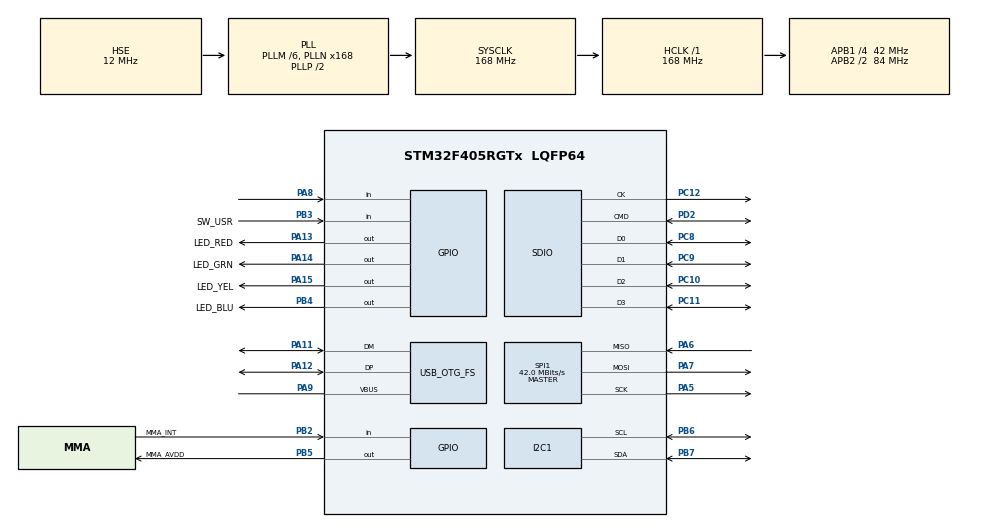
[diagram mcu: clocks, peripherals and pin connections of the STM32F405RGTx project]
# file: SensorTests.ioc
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Dma.Request0=SDIO_RX
Dma.Request1=SDIO_TX
Dma.SDIO_RX.0.Direction=DMA_PERIPH_TO_MEMORY
Dma.SDIO_RX.0.FIFOMode=DMA_FIFOMODE_ENABLE
Dma.SDIO_RX.0.FIFOThreshold=DMA_FIFO_THRESHOLD_FULL
Dma.SDIO_RX.0.Instance=DMA2_Stream3
Dma.SDIO_RX.0.MemBurst=DMA_MBURST_INC4
Dma.SDIO_RX.0.MemDataAlignment=DMA_MDATAALIGN_WORD
Dma.SDIO_RX.0.MemInc=DMA_MINC_ENABLE
Dma.SDIO_RX.0.Mode=DMA_PFCTRL
Dma.SDIO_RX.0.PeriphBurst=DMA_PBURST_INC4
Dma.SDIO_RX.0.PeriphDataAlignment=DMA_PDATAALIGN_WORD
Dma.SDIO_RX.0.PeriphInc=DMA_PINC_DISABLE
Dma.SDIO_RX.0.Priority=DMA_PRIORITY_LOW
Dma.SDIO_TX.1.Direction=DMA_MEMORY_TO_PERIPH
Dma.SDIO_TX.1.FIFOMode=DMA_FIFOMODE_ENABLE
Dma.SDIO_TX.1.FIFOThreshold=DMA_FIFO_THRESHOLD_FULL
Dma.SDIO_TX.1.Instance=DMA2_Stream6
Dma.SDIO_TX.1.MemBurst=DMA_MBURST_INC4
Dma.SDIO_TX.1.MemDataAlignment=DMA_MDATAALIGN_WORD
Dma.SDIO_TX.1.MemInc=DMA_MINC_ENABLE
Dma.SDIO_TX.1.Mode=DMA_PFCTRL
Dma.SDIO_TX.1.PeriphBurst=DMA_PBURST_INC4
Dma.SDIO_TX.1.PeriphDataAlignment=DMA_PDATAALIGN_WORD
Dma.SDIO_TX.1.PeriphInc=DMA_PINC_DISABLE
Dma.SDIO_TX.1.Priority=DMA_PRIORITY_LOW
FATFS.BSP.number=1
FATFS.USE_DMA_CODE_SD=1
FATFS0.BSP.STBoard=false
FATFS0.BSP.api=Unknown
FATFS0.BSP.i2caddr=0
FATFS0.BSP.instance=PA8
FATFS0.BSP.ip=GPIO
FATFS0.BSP.mode=Input
FATFS0.BSP.name=Detect_SDIO
FATFS0.BSP.solution=PA8
Mcu.Family=STM32F4
Mcu.Name=STM32F405RGTx
Mcu.Package=LQFP64
NVIC.DMA2_Stream3_IRQn=true\:0\:0\:false\:false\:true\:false\:true
NVIC.DMA2_Stream6_IRQn=true\:0\:0\:false\:false\:true\:false\:true
NVIC.OTG_FS_IRQn=true\:0\:0\:false\:false\:true\:false\:true
NVIC.PriorityGroup=NVIC_PRIORITYGROUP_4
NVIC.SDIO_IRQn=true\:0\:0\:false\:false\:true\:true\:true
PA11.Mode=Device_Only
PA11.Signal=USB_OTG_FS_DM
PA12.Mode=Device_Only
PA12.Signal=USB_OTG_FS_DP
PA13.GPIO_Label=LED_RED
PA13.Signal=GPIO_Output
PA14.GPIO_Label=LED_GRN
PA14.Signal=GPIO_Output
PA15.GPIO_Label=LED_YEL
PA15.Signal=GPIO_Output
PA5.Mode=Full_Duplex_Master
PA5.Signal=SPI1_SCK
PA6.Mode=Full_Duplex_Master
PA6.Signal=SPI1_MISO
PA7.Mode=Full_Duplex_Master
PA7.Signal=SPI1_MOSI
PA8.Signal=GPIO_Input
PA9.Mode=Activate_VBUS
PA9.Signal=USB_OTG_FS_VBUS
PB2.GPIO_Label=MMA_INT
PB2.Signal=GPIO_Input
PB3.GPIO_Label=SW_USR
PB3.Signal=GPIO_Input
PB4.GPIO_Label=LED_BLU
PB4.Signal=GPIO_Output
PB5.GPIO_Label=MMA_AVDD
PB5.Signal=GPIO_Output
PB6.GPIO_PuPdOD=GPIO_NOPULL
PB6.Mode=I2C
PB6.Signal=I2C1_SCL
PB7.GPIO_PuPdOD=GPIO_NOPULL
PB7.Mode=I2C
PB7.Signal=I2C1_SDA
PC10.GPIO_PuPd=GPIO_PULLUP
PC10.Mode=SD_4_bits_Wide_bus
PC10.Signal=SDIO_D2
PC11.Mode=SD_4_bits_Wide_bus
PC11.Signal=SDIO_D3
PC12.GPIO_PuPd=GPIO_NOPULL
PC12.Mode=SD_4_bits_Wide_bus
PC12.Signal=SDIO_CK
PC14-OSC32_IN.Mode=LSE-External-Oscillator
PC14-OSC32_IN.Signal=RCC_OSC32_IN
PC15-OSC32_OUT.Mode=LSE-External-Oscillator
PC15-OSC32_OUT.Signal=RCC_OSC32_OUT
PC8.GPIO_PuPd=GPIO_PULLUP
PC8.Mode=SD_4_bits_Wide_bus
PC8.Signal=SDIO_D0
PC9.GPIO_PuPd=GPIO_PULLUP
PC9.Mode=SD_4_bits_Wide_bus
PC9.Signal=SDIO_D1
PD2.GPIO_PuPd=GPIO_PULLUP
PD2.Mode=SD_4_bits_Wide_bus
PD2.Signal=SDIO_CMD
PH0-OSC_IN.Mode=HSE-External-Oscillator
PH0-OSC_IN.Signal=RCC_OSC_IN
PH1-OSC_OUT.Mode=HSE-External-Oscillator
PH1-OSC_OUT.Signal=RCC_OSC_OUT
ProjectManager.HeapSize=0x200
ProjectManager.StackSize=0x400
ProjectManager.TargetToolchain=STM32CubeIDE
RCC.48MHZClocksFreq_Value=48000000
RCC.AHBFreq_Value=168000000
RCC.APB1CLKDivider=RCC_HCLK_DIV4
RCC.APB1Freq_Value=42000000
RCC.APB1TimFreq_Value=84000000
RCC.APB2CLKDivider=RCC_HCLK_DIV2
RCC.APB2Freq_Value=84000000
RCC.APB2TimFreq_Value=168000000
RCC.CortexFreq_Value=168000000
RCC.HCLKFreq_Value=168000000
RCC.HSE_VALUE=12000000
RCC.HSI_VALUE=16000000
RCC.PLLM=6
RCC.PLLN=168
RCC.PLLQ=7
RCC.SYSCLKFreq_VALUE=168000000
RCC.SYSCLKSource=RCC_SYSCLKSOURCE_PLLCLK
RCC.VCOOutputFreq_Value=336000000
SPI1.CalculateBaudRate=42.0 MBits/s
SPI1.Direction=SPI_DIRECTION_2LINES
SPI1.Mode=SPI_MODE_MASTER
SPI1.VirtualType=VM_MASTER
USB_DEVICE.CLASS_NAME_FS=CDC
USB_DEVICE.VirtualMode-CDC_FS=Cdc
USB_DEVICE.VirtualModeFS=Cdc_FS
USB_OTG_FS.VirtualMode=Device_Only
VP_FATFS_VS_SDIO.Mode=SDIO
VP_USB_DEVICE_VS_USB_DEVICE_CDC_FS.Mode=CDC_FS
board=custom

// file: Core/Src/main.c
/* USER CODE BEGIN Header */
/**
  ******************************************************************************
  * @file           : main.c
  * @brief          : Main program body
  ******************************************************************************
  * @attention
  *
  * <h2><center>&copy; Copyright (c) 2020 STMicroelectronics.
  * All rights reserved.</center></h2>
  *
  * This software component is licensed by ST under Ultimate Liberty license
  * SLA0044, the "License"; You may not use this file except in compliance with
  * the License. You may obtain a copy of the License at:
  *                             www.st.com/SLA0044
  *
  ******************************************************************************
  */
/* USER CODE END Header */

#include "main.h"
#include "fatfs.h"
#include "usb_device.h"

/* USER CODE BEGIN Includes */
#include "run.c"
/* USER CODE END Includes */

I2C_HandleTypeDef hi2c1;

SD_HandleTypeDef hsd;
DMA_HandleTypeDef hdma_sdio_rx;
DMA_HandleTypeDef hdma_sdio_tx;

SPI_HandleTypeDef hspi1;

void SystemClock_Config(void);
static void MX_GPIO_Init(void);
static void MX_DMA_Init(void);
static void MX_SDIO_SD_Init(void);
static void MX_I2C1_Init(void);
static void MX_SPI1_Init(void);

int main(void)
{

  /* MCU Configuration--------------------------------------------------------*/

  /* Reset of all peripherals, Initializes the Flash interface and the Systick. */
  HAL_Init();

  /* Configure the system clock */
  SystemClock_Config();

  /* Initialize all configured peripherals */
  MX_GPIO_Init();
  MX_DMA_Init();
  MX_SDIO_SD_Init();
  MX_FATFS_Init();
  MX_I2C1_Init();
  MX_SPI1_Init();
  MX_USB_DEVICE_Init();
  /* USER CODE BEGIN 2 */
  setup();
  /* USER CODE END 2 */

  /* Infinite loop */
  while (1)
  {

    /* USER CODE BEGIN 3 */
	loop();
  }
  /* USER CODE END 3 */
}

void SystemClock_Config(void)
{
  RCC_OscInitTypeDef RCC_OscInitStruct = {0};
  RCC_ClkInitTypeDef RCC_ClkInitStruct = {0};

  /** Configure the main internal regulator output voltage
  */
  __HAL_RCC_PWR_CLK_ENABLE();
  __HAL_PWR_VOLTAGESCALING_CONFIG(PWR_REGULATOR_VOLTAGE_SCALE1);
  /** Initializes the CPU, AHB and APB busses clocks
  */
  RCC_OscInitStruct.OscillatorType = RCC_OSCILLATORTYPE_HSE;
  RCC_OscInitStruct.HSEState = RCC_HSE_ON;
  RCC_OscInitStruct.PLL.PLLState = RCC_PLL_ON;
  RCC_OscInitStruct.PLL.PLLSource = RCC_PLLSOURCE_HSE;
  RCC_OscInitStruct.PLL.PLLM = 6;
  RCC_OscInitStruct.PLL.PLLN = 168;
  RCC_OscInitStruct.PLL.PLLP = RCC_PLLP_DIV2;
  RCC_OscInitStruct.PLL.PLLQ = 7;
  if (HAL_RCC_OscConfig(&RCC_OscInitStruct) != HAL_OK)
  {
    Error_Handler();
  }
  /** Initializes the CPU, AHB and APB busses clocks
  */
  RCC_ClkInitStruct.ClockType = RCC_CLOCKTYPE_HCLK|RCC_CLOCKTYPE_SYSCLK
                              |RCC_CLOCKTYPE_PCLK1|RCC_CLOCKTYPE_PCLK2;
  RCC_ClkInitStruct.SYSCLKSource = RCC_SYSCLKSOURCE_PLLCLK;
  RCC_ClkInitStruct.AHBCLKDivider = RCC_SYSCLK_DIV1;
  RCC_ClkInitStruct.APB1CLKDivider = RCC_HCLK_DIV4;
  RCC_ClkInitStruct.APB2CLKDivider = RCC_HCLK_DIV2;

  if (HAL_RCC_ClockConfig(&RCC_ClkInitStruct, FLASH_LATENCY_5) != HAL_OK)
  {
    Error_Handler();
  }
}

static void MX_I2C1_Init(void)
{

  hi2c1.Instance = I2C1;
  hi2c1.Init.ClockSpeed = 100000;
  hi2c1.Init.DutyCycle = I2C_DUTYCYCLE_2;
  hi2c1.Init.OwnAddress1 = 0;
  hi2c1.Init.AddressingMode = I2C_ADDRESSINGMODE_7BIT;
  hi2c1.Init.DualAddressMode = I2C_DUALADDRESS_DISABLE;
  hi2c1.Init.OwnAddress2 = 0;
  hi2c1.Init.GeneralCallMode = I2C_GENERALCALL_DISABLE;
  hi2c1.Init.NoStretchMode = I2C_NOSTRETCH_DISABLE;
  if (HAL_I2C_Init(&hi2c1) != HAL_OK)
  {
    Error_Handler();
  }

}

static void MX_SDIO_SD_Init(void)
{

  hsd.Instance = SDIO;
  hsd.Init.ClockEdge = SDIO_CLOCK_EDGE_RISING;
  hsd.Init.ClockBypass = SDIO_CLOCK_BYPASS_DISABLE;
  hsd.Init.ClockPowerSave = SDIO_CLOCK_POWER_SAVE_DISABLE;
  hsd.Init.BusWide = SDIO_BUS_WIDE_1B;
  hsd.Init.HardwareFlowControl = SDIO_HARDWARE_FLOW_CONTROL_DISABLE;
  hsd.Init.ClockDiv = 0;

}

static void MX_SPI1_Init(void)
{

  /* SPI1 parameter configuration*/
  hspi1.Instance = SPI1;
  hspi1.Init.Mode = SPI_MODE_MASTER;
  hspi1.Init.Direction = SPI_DIRECTION_2LINES;
  hspi1.Init.DataSize = SPI_DATASIZE_8BIT;
  hspi1.Init.CLKPolarity = SPI_POLARITY_LOW;
  hspi1.Init.CLKPhase = SPI_PHASE_1EDGE;
  hspi1.Init.NSS = SPI_NSS_SOFT;
  hspi1.Init.BaudRatePrescaler = SPI_BAUDRATEPRESCALER_2;
  hspi1.Init.FirstBit = SPI_FIRSTBIT_MSB;
  hspi1.Init.TIMode = SPI_TIMODE_DISABLE;
  hspi1.Init.CRCCalculation = SPI_CRCCALCULATION_DISABLE;
  hspi1.Init.CRCPolynomial = 10;
  if (HAL_SPI_Init(&hspi1) != HAL_OK)
  {
    Error_Handler();
  }

}

static void MX_DMA_Init(void)
{

  /* DMA controller clock enable */
  __HAL_RCC_DMA2_CLK_ENABLE();

  /* DMA interrupt init */
  /* DMA2_Stream3_IRQn interrupt configuration */
  HAL_NVIC_SetPriority(DMA2_Stream3_IRQn, 0, 0);
  HAL_NVIC_EnableIRQ(DMA2_Stream3_IRQn);
  /* DMA2_Stream6_IRQn interrupt configuration */
  HAL_NVIC_SetPriority(DMA2_Stream6_IRQn, 0, 0);
  HAL_NVIC_EnableIRQ(DMA2_Stream6_IRQn);

}

static void MX_GPIO_Init(void)
{
  GPIO_InitTypeDef GPIO_InitStruct = {0};

  /* GPIO Ports Clock Enable */
  __HAL_RCC_GPIOC_CLK_ENABLE();
  __HAL_RCC_GPIOH_CLK_ENABLE();
  __HAL_RCC_GPIOA_CLK_ENABLE();
  __HAL_RCC_GPIOB_CLK_ENABLE();
  __HAL_RCC_GPIOD_CLK_ENABLE();

  /*Configure GPIO pin Output Level */
  HAL_GPIO_WritePin(GPIOA, LED_RED_Pin|LED_GRN_Pin|LED_YEL_Pin, GPIO_PIN_RESET);

  /*Configure GPIO pin Output Level */
  HAL_GPIO_WritePin(GPIOB, LED_BLU_Pin|MMA_AVDD_Pin, GPIO_PIN_RESET);

  /*Configure GPIO pins : MMA_INT_Pin SW_USR_Pin */
  GPIO_InitStruct.Pin = MMA_INT_Pin|SW_USR_Pin;
  GPIO_InitStruct.Mode = GPIO_MODE_INPUT;
  GPIO_InitStruct.Pull = GPIO_NOPULL;
  HAL_GPIO_Init(GPIOB, &GPIO_InitStruct);

  /*Configure GPIO pin : PA8 */
  GPIO_InitStruct.Pin = GPIO_PIN_8;
  GPIO_InitStruct.Mode = GPIO_MODE_INPUT;
  GPIO_InitStruct.Pull = GPIO_NOPULL;
  HAL_GPIO_Init(GPIOA, &GPIO_InitStruct);

  /*Configure GPIO pins : LED_RED_Pin LED_GRN_Pin LED_YEL_Pin */
  GPIO_InitStruct.Pin = LED_RED_Pin|LED_GRN_Pin|LED_YEL_Pin;
  GPIO_InitStruct.Mode = GPIO_MODE_OUTPUT_PP;
  GPIO_InitStruct.Pull = GPIO_NOPULL;
  GPIO_InitStruct.Speed = GPIO_SPEED_FREQ_LOW;
  HAL_GPIO_Init(GPIOA, &GPIO_InitStruct);

  /*Configure GPIO pins : LED_BLU_Pin MMA_AVDD_Pin */
  GPIO_InitStruct.Pin = LED_BLU_Pin|MMA_AVDD_Pin;
  GPIO_InitStruct.Mode = GPIO_MODE_OUTPUT_PP;
  GPIO_InitStruct.Pull = GPIO_NOPULL;
  GPIO_InitStruct.Speed = GPIO_SPEED_FREQ_LOW;
  HAL_GPIO_Init(GPIOB, &GPIO_InitStruct);

}

/* USER CODE BEGIN 4 */

I2C_HandleTypeDef* Get_I2C1_Instance()
{
	return &hi2c1;
}

SPI_HandleTypeDef* Get_SPI1_Instance()
{
	return &hspi1;
}

/* USER CODE END 4 */

void Error_Handler(void)
{
}

/************************ (C) COPYRIGHT STMicroelectronics *****END OF FILE****/
